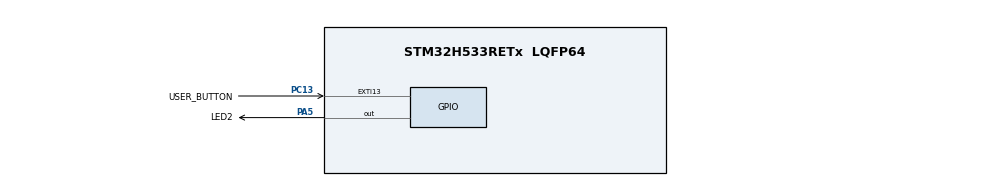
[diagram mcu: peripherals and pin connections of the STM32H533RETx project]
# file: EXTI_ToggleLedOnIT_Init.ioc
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BOOTPATH.BootPathName=LEGACY
BOOTPATH.UserSelectedBootPath=LEGACY
CORTEX_M33_NS.userName=CORTEX_M33
Mcu.Family=STM32H5
Mcu.Name=STM32H533RETx
Mcu.Package=LQFP64
NVIC.EXTI13_IRQn=true\:0\:0\:false\:false\:true\:true\:true\:true
NVIC.PriorityGroup=NVIC_PRIORITYGROUP_4
PA5.GPIO_Label=LED2
PA5.Signal=GPIO_Output
PC13.GPIO_Label=USER_BUTTON
PC13.GPIO_PuPd=GPIO_PULLDOWN
PC13.Signal=GPXTI13
PH0-OSC_IN(PH0).Mode=HSE-External-Oscillator
PH0-OSC_IN(PH0).Signal=RCC_OSC_IN
PH1-OSC_OUT(PH1).Mode=HSE-External-Oscillator
PH1-OSC_OUT(PH1).Signal=RCC_OSC_OUT
ProjectManager.HeapSize=0x200
ProjectManager.StackSize=0x400
ProjectManager.TargetToolchain=EWARM V9.20
RCC.ADCFreq_Value=250000000
RCC.AHBFreq_Value=250000000
RCC.APB1Freq_Value=250000000
RCC.APB1TimFreq_Value=250000000
RCC.APB2Freq_Value=250000000
RCC.APB2TimFreq_Value=250000000
RCC.APB3Freq_Value=250000000
RCC.CSI_VALUE=4000000
RCC.CortexFreq_Value=250000000
RCC.EPOD_VALUE=24000000
RCC.HCLKFreq_Value=250000000
RCC.HSE_VALUE=24000000
RCC.HSI48_VALUE=48000000
RCC.HSI_VALUE=64000000
RCC.LSE_VALUE=32768
RCC.LSIRC_VALUE=32000
RCC.PLLM=12
RCC.PLLN=250
RCC.PLLSourceVirtual=RCC_PLL1_SOURCE_HSE
RCC.SYSCLKFreq_VALUE=250000000
RCC.SYSCLKSource=RCC_SYSCLKSOURCE_PLLCLK
RCC.USBFreq_Value=48000000
RCC.VCOOutputFreq_Value=500000000
VP_BOOTPATH_VS_BOOTPATH.Mode=BP_Activate
VP_ICACHE_VS_ICACHE.Mode=DefaultMode
VP_MEMORYMAP_VS_MEMORYMAP.Mode=CurAppReg
VP_PWR_VS_DBSignals.Mode=DisableDeadBatterySignals
VP_PWR_VS_LPOM.Mode=PowerOptimisation
VP_PWR_VS_SECSignals.Mode=Security/Privilege
board=custom

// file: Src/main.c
/* USER CODE BEGIN Header */
/**
  ******************************************************************************
  * @file    Examples_LL/EXTI/EXTI_ToggleLedOnIT_Init/Src/main.c
  * @author  MCD Application Team
  * @brief   This example describes how to configure the EXTI and use
  *          GPIOs using the STM32H5xx LL API to toggles the available
  *          users Leds on the board when User button is pressed.
  *          Peripheral initialization done using LL initialization function.
  ******************************************************************************
  * @attention
  *
  * Copyright (c) 2023 STMicroelectronics.
  * All rights reserved.
  *
  * This software is licensed under terms that can be found in the LICENSE file
  * in the root directory of this software component.
  * If no LICENSE file comes with this software, it is provided AS-IS.
  *
  ******************************************************************************
  */
/* USER CODE END Header */
#include "main.h"

void SystemClock_Config(void);
static void MX_GPIO_Init(void);
static void MX_ICACHE_Init(void);

int main(void)
{

  /* MCU Configuration--------------------------------------------------------*/

  /* Reset of all peripherals, Initializes the Flash interface and the Systick. */

  /* System interrupt init*/
  NVIC_SetPriorityGrouping(NVIC_PRIORITYGROUP_4);

  /* Disable the internal Pull-Up in Dead Battery pins of UCPD peripheral */
  LL_PWR_DisableUCPDDeadBattery();

  /* Configure the system clock */
  SystemClock_Config();

  /* Initialize all configured peripherals */
  MX_GPIO_Init();
  MX_ICACHE_Init();

  /* Infinite loop */
  while (1)
  {

  }
}

void SystemClock_Config(void)
{
  LL_FLASH_SetLatency(LL_FLASH_LATENCY_5);
  while(LL_FLASH_GetLatency()!= LL_FLASH_LATENCY_5)
  {
  }

  LL_PWR_SetRegulVoltageScaling(LL_PWR_REGU_VOLTAGE_SCALE0);
  while (LL_PWR_IsActiveFlag_VOS() == 0)
  {
  }
  LL_RCC_HSE_Enable();

   /* Wait till HSE is ready */
  while(LL_RCC_HSE_IsReady() != 1)
  {
  }

  LL_RCC_PLL1_SetSource(LL_RCC_PLL1SOURCE_HSE);
  LL_RCC_PLL1_SetVCOInputRange(LL_RCC_PLLINPUTRANGE_2_4);
  LL_RCC_PLL1_SetVCOOutputRange(LL_RCC_PLLVCORANGE_WIDE);
  LL_RCC_PLL1_SetM(12);
  LL_RCC_PLL1_SetN(250);
  LL_RCC_PLL1_SetP(2);
  LL_RCC_PLL1_SetQ(2);
  LL_RCC_PLL1_SetR(2);
  LL_RCC_PLL1P_Enable();
  LL_RCC_PLL1_Enable();

   /* Wait till PLL is ready */
  while(LL_RCC_PLL1_IsReady() != 1)
  {
  }

  LL_RCC_SetSysClkSource(LL_RCC_SYS_CLKSOURCE_PLL1);

   /* Wait till System clock is ready */
  while(LL_RCC_GetSysClkSource() != LL_RCC_SYS_CLKSOURCE_STATUS_PLL1)
  {
  }

  LL_RCC_SetAHBPrescaler(LL_RCC_SYSCLK_DIV_1);
  LL_RCC_SetAPB1Prescaler(LL_RCC_APB1_DIV_1);
  LL_RCC_SetAPB2Prescaler(LL_RCC_APB2_DIV_1);
  LL_RCC_SetAPB3Prescaler(LL_RCC_APB3_DIV_1);

  LL_Init1msTick(250000000);

  LL_SetSystemCoreClock(250000000);
}

static void MX_ICACHE_Init(void)
{

  /** Enable instruction cache (default 2-ways set associative cache)
  */
  LL_ICACHE_Enable();

}

static void MX_GPIO_Init(void)
{
  LL_EXTI_InitTypeDef EXTI_InitStruct = {0};
  LL_GPIO_InitTypeDef GPIO_InitStruct = {0};

  /* GPIO Ports Clock Enable */
  LL_AHB2_GRP1_EnableClock(LL_AHB2_GRP1_PERIPH_GPIOC);
  LL_AHB2_GRP1_EnableClock(LL_AHB2_GRP1_PERIPH_GPIOH);
  LL_AHB2_GRP1_EnableClock(LL_AHB2_GRP1_PERIPH_GPIOA);

  /**/
  LL_GPIO_ResetOutputPin(LED2_GPIO_Port, LED2_Pin);

  /**/
  LL_EXTI_SetEXTISource(LL_EXTI_EXTI_PORTC, LL_EXTI_EXTI_LINE13);

  /**/
  EXTI_InitStruct.Line_0_31 = LL_EXTI_LINE_13;
  EXTI_InitStruct.Line_32_63 = LL_EXTI_LINE_NONE;
  EXTI_InitStruct.LineCommand = ENABLE;
  EXTI_InitStruct.Mode = LL_EXTI_MODE_IT;
  EXTI_InitStruct.Trigger = LL_EXTI_TRIGGER_RISING;
  LL_EXTI_Init(&EXTI_InitStruct);

  /**/
  LL_GPIO_SetPinPull(USER_BUTTON_GPIO_Port, USER_BUTTON_Pin, LL_GPIO_PULL_DOWN);

  /**/
  LL_GPIO_SetPinMode(USER_BUTTON_GPIO_Port, USER_BUTTON_Pin, LL_GPIO_MODE_INPUT);

  /**/
  GPIO_InitStruct.Pin = LED2_Pin;
  GPIO_InitStruct.Mode = LL_GPIO_MODE_OUTPUT;
  GPIO_InitStruct.Speed = LL_GPIO_SPEED_FREQ_LOW;
  GPIO_InitStruct.OutputType = LL_GPIO_OUTPUT_PUSHPULL;
  GPIO_InitStruct.Pull = LL_GPIO_PULL_NO;
  LL_GPIO_Init(LED2_GPIO_Port, &GPIO_InitStruct);

  /* EXTI interrupt init*/
  NVIC_SetPriority(EXTI13_IRQn, NVIC_EncodePriority(NVIC_GetPriorityGrouping(),0, 0));
  NVIC_EnableIRQ(EXTI13_IRQn);

}

/* USER CODE BEGIN 4 */

/******************************************************************************/
/*   USER IRQ HANDLER TREATMENT                                               */
/******************************************************************************/
/**
  * @brief  Function to manage IRQ Handler
  * @param  None
  * @retval None
  */
void UserButton_Callback(void)
{
  LL_GPIO_TogglePin(LED2_GPIO_Port, LED2_Pin);
}

/* USER CODE END 4 */

void Error_Handler(void)
{
  /* USER CODE BEGIN Error_Handler_Debug */
  /* User can add his own implementation to report the HAL error return state */
  /*Infinite loop */
  while (1)
  {
  }
  /* USER CODE END Error_Handler_Debug */
}

#ifdef  USE_FULL_ASSERT
/**
  * @brief  Reports the name of the source file and the source line number
  *         where the assert_param error has occurred.
  * @param  file: pointer to the source file name
  * @param  line: assert_param error line source number
  * @retval None
  */
void assert_failed(uint8_t *file, uint32_t line)
{
  /* USER CODE BEGIN 6 */
  /* User can add his own implementation to report the file name and line number,
     tex: printf("Wrong parameters value: file %s on line %d\r\n", file, line) */
  /*Infinite loop */
  while (1)
  {
  }
  /* USER CODE END 6 */
}
#endif /* USE_FULL_ASSERT */
